# dmpac_targetdb register map
Vendor: Texas Instruments
Registers are 32-bit, read-write, no defined reset value unless marked. A register's access mark holds for its fields unless they carry their own. Offsets are as the file gives them; [hi:lo] are bit positions; {n}, {i} and the like mark numbered series; 'fields as' and 'values as' point back to an identical list.

## DMPAC (part 3 of 5) — Depth and Motion Perception Accelerator (DMPAC)
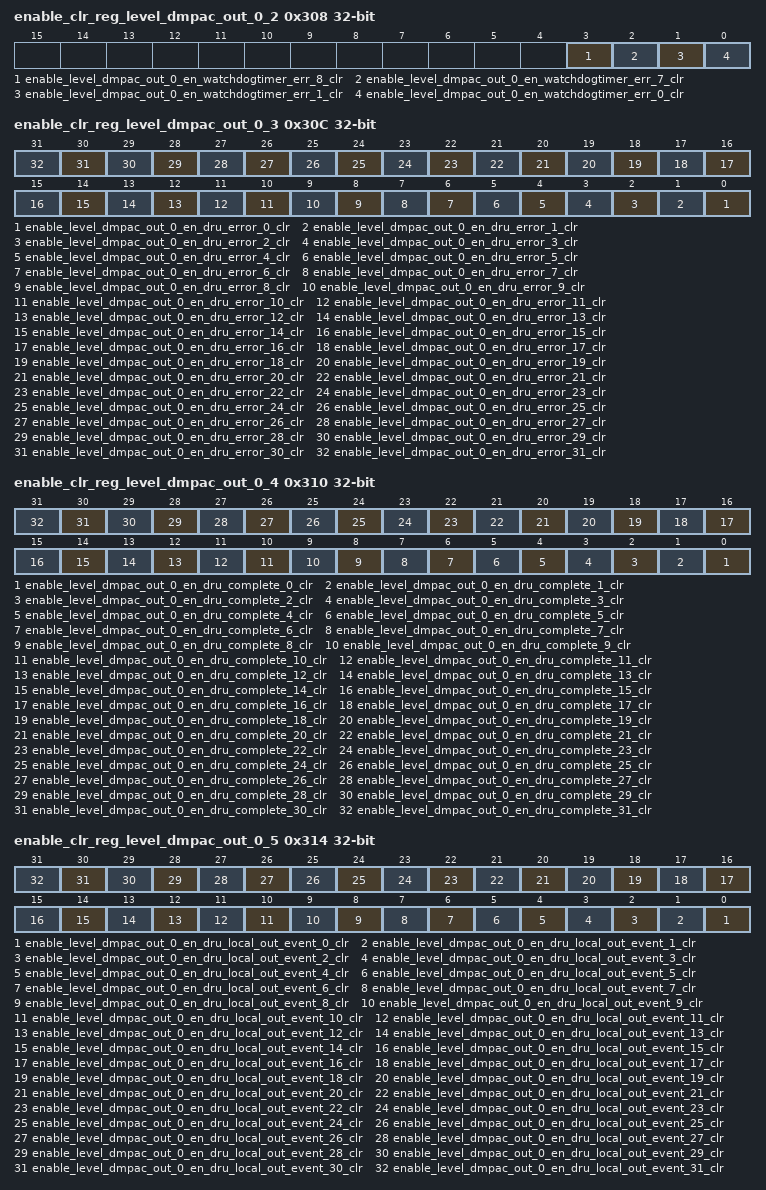
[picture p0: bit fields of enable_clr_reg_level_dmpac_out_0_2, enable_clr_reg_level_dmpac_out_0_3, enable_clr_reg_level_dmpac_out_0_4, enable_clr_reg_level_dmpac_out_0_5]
0x308 enable_clr_reg_level_dmpac_out_0_2 — Enable Clear Register 2
  [3] enable_level_dmpac_out_0_en_watchdogtimer_err_8_clr — Enable Clear for level_dmpac_out_0_en_watchdogtimer_err_8
  [2] enable_level_dmpac_out_0_en_watchdogtimer_err_7_clr — Enable Clear for level_dmpac_out_0_en_watchdogtimer_err_7
  [1] enable_level_dmpac_out_0_en_watchdogtimer_err_1_clr — Enable Clear for level_dmpac_out_0_en_watchdogtimer_err_1
  [0] enable_level_dmpac_out_0_en_watchdogtimer_err_0_clr — Enable Clear for level_dmpac_out_0_en_watchdogtimer_err_0
0x30C enable_clr_reg_level_dmpac_out_0_3 — Enable Clear Register 3
  [n] enable_level_dmpac_out_0_en_dru_error_{n}_clr (n=0..31) — Enable Clear for level_dmpac_out_0_en_dru_error_{n}
0x310 enable_clr_reg_level_dmpac_out_0_4 — Enable Clear Register 4
  [n] enable_level_dmpac_out_0_en_dru_complete_{n}_clr (n=0..31) — Enable Clear for level_dmpac_out_0_en_dru_complete_{n}
0x314 enable_clr_reg_level_dmpac_out_0_5 — Enable Clear Register 5
  [n] enable_level_dmpac_out_0_en_dru_local_out_event_{n}_clr (n=0..31) — Enable Clear for level_dmpac_out_0_en_dru_local_out_event_{n}
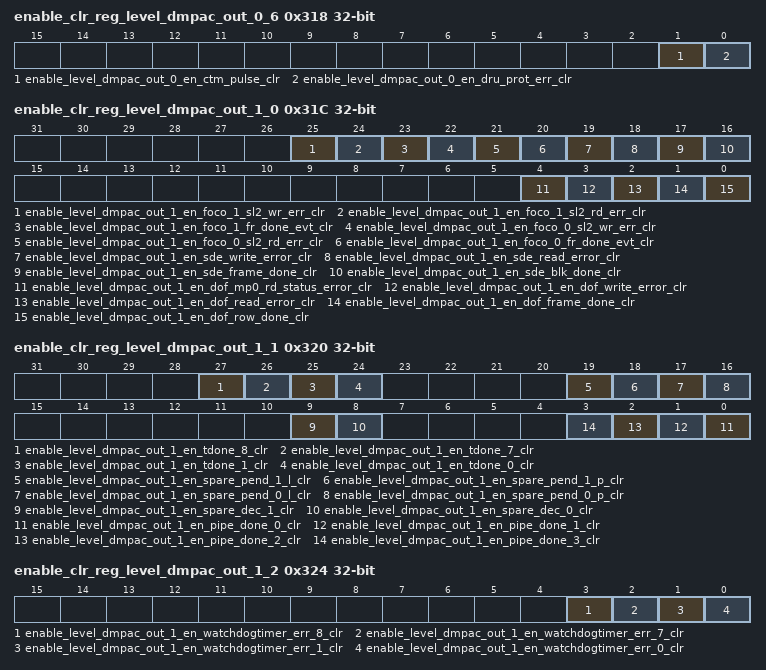
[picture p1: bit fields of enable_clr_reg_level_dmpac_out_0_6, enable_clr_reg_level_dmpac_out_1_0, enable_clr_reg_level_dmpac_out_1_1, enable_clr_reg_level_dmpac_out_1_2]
0x318 enable_clr_reg_level_dmpac_out_0_6 — Enable Clear Register 6
  [1] enable_level_dmpac_out_0_en_ctm_pulse_clr — Enable Clear for level_dmpac_out_0_en_ctm_pulse
  [0] enable_level_dmpac_out_0_en_dru_prot_err_clr — Enable Clear for level_dmpac_out_0_en_dru_prot_err
0x31C enable_clr_reg_level_dmpac_out_1_0 — Enable Clear Register 7
  [25] enable_level_dmpac_out_1_en_foco_1_sl2_wr_err_clr — Enable Clear for level_dmpac_out_1_en_foco_1_sl2_wr_err
  [24] enable_level_dmpac_out_1_en_foco_1_sl2_rd_err_clr — Enable Clear for level_dmpac_out_1_en_foco_1_sl2_rd_err
  [23] enable_level_dmpac_out_1_en_foco_1_fr_done_evt_clr — Enable Clear for level_dmpac_out_1_en_foco_1_fr_done_evt
  [22] enable_level_dmpac_out_1_en_foco_0_sl2_wr_err_clr — Enable Clear for level_dmpac_out_1_en_foco_0_sl2_wr_err
  [21] enable_level_dmpac_out_1_en_foco_0_sl2_rd_err_clr — Enable Clear for level_dmpac_out_1_en_foco_0_sl2_rd_err
  [20] enable_level_dmpac_out_1_en_foco_0_fr_done_evt_clr — Enable Clear for level_dmpac_out_1_en_foco_0_fr_done_evt
  [19] enable_level_dmpac_out_1_en_sde_write_error_clr — Enable Clear for level_dmpac_out_1_en_sde_write_error
  [18] enable_level_dmpac_out_1_en_sde_read_error_clr — Enable Clear for level_dmpac_out_1_en_sde_read_error
  [17] enable_level_dmpac_out_1_en_sde_frame_done_clr — Enable Clear for level_dmpac_out_1_en_sde_frame_done
  [16] enable_level_dmpac_out_1_en_sde_blk_done_clr — Enable Clear for level_dmpac_out_1_en_sde_blk_done
  [4] enable_level_dmpac_out_1_en_dof_mp0_rd_status_error_clr — Enable Clear for level_dmpac_out_1_en_dof_mp0_rd_status_error
  [3] enable_level_dmpac_out_1_en_dof_write_error_clr — Enable Clear for level_dmpac_out_1_en_dof_write_error
  [2] enable_level_dmpac_out_1_en_dof_read_error_clr — Enable Clear for level_dmpac_out_1_en_dof_read_error
  [1] enable_level_dmpac_out_1_en_dof_frame_done_clr — Enable Clear for level_dmpac_out_1_en_dof_frame_done
  [0] enable_level_dmpac_out_1_en_dof_row_done_clr — Enable Clear for level_dmpac_out_1_en_dof_row_done
0x320 enable_clr_reg_level_dmpac_out_1_1 — Enable Clear Register 8
  [27] enable_level_dmpac_out_1_en_tdone_8_clr — Enable Clear for level_dmpac_out_1_en_tdone_8
  [26] enable_level_dmpac_out_1_en_tdone_7_clr — Enable Clear for level_dmpac_out_1_en_tdone_7
  [25] enable_level_dmpac_out_1_en_tdone_1_clr — Enable Clear for level_dmpac_out_1_en_tdone_1
  [24] enable_level_dmpac_out_1_en_tdone_0_clr — Enable Clear for level_dmpac_out_1_en_tdone_0
  [19] enable_level_dmpac_out_1_en_spare_pend_1_l_clr — Enable Clear for level_dmpac_out_1_en_spare_pend_1_l
  [18] enable_level_dmpac_out_1_en_spare_pend_1_p_clr — Enable Clear for level_dmpac_out_1_en_spare_pend_1_p
  [17] enable_level_dmpac_out_1_en_spare_pend_0_l_clr — Enable Clear for level_dmpac_out_1_en_spare_pend_0_l
  [16] enable_level_dmpac_out_1_en_spare_pend_0_p_clr — Enable Clear for level_dmpac_out_1_en_spare_pend_0_p
  [9] enable_level_dmpac_out_1_en_spare_dec_1_clr — Enable Clear for level_dmpac_out_1_en_spare_dec_1
  [8] enable_level_dmpac_out_1_en_spare_dec_0_clr — Enable Clear for level_dmpac_out_1_en_spare_dec_0
  [n] enable_level_dmpac_out_1_en_pipe_done_{n}_clr (n=0..3) — Enable Clear for level_dmpac_out_1_en_pipe_done_{n}
0x324 enable_clr_reg_level_dmpac_out_1_2 — Enable Clear Register 9
  [3] enable_level_dmpac_out_1_en_watchdogtimer_err_8_clr — Enable Clear for level_dmpac_out_1_en_watchdogtimer_err_8
  [2] enable_level_dmpac_out_1_en_watchdogtimer_err_7_clr — Enable Clear for level_dmpac_out_1_en_watchdogtimer_err_7
  [1] enable_level_dmpac_out_1_en_watchdogtimer_err_1_clr — Enable Clear for level_dmpac_out_1_en_watchdogtimer_err_1
  [0] enable_level_dmpac_out_1_en_watchdogtimer_err_0_clr — Enable Clear for level_dmpac_out_1_en_watchdogtimer_err_0
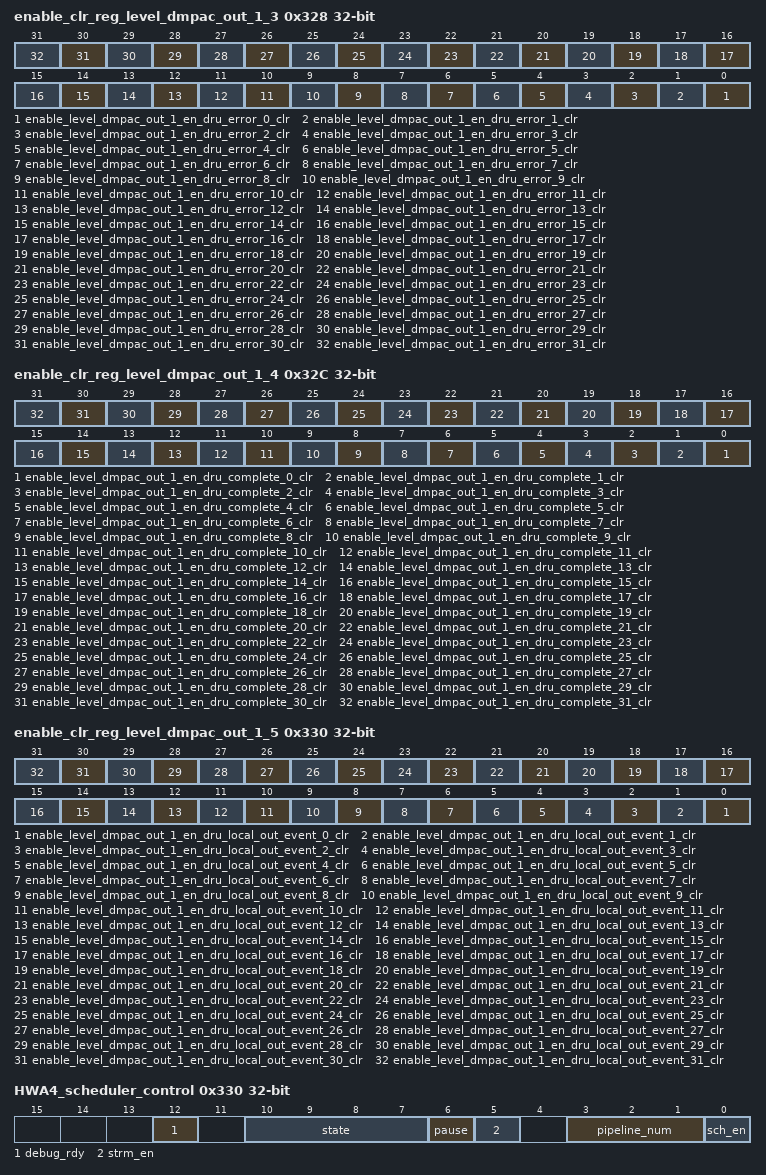
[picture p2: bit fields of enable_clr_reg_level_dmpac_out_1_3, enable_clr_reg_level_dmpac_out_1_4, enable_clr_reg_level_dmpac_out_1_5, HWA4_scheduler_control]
0x328 enable_clr_reg_level_dmpac_out_1_3 — Enable Clear Register 10
  [n] enable_level_dmpac_out_1_en_dru_error_{n}_clr (n=0..31) — Enable Clear for level_dmpac_out_1_en_dru_error_{n}
0x32C enable_clr_reg_level_dmpac_out_1_4 — Enable Clear Register 11
  [n] enable_level_dmpac_out_1_en_dru_complete_{n}_clr (n=0..31) — Enable Clear for level_dmpac_out_1_en_dru_complete_{n}
0x330 enable_clr_reg_level_dmpac_out_1_5 — Enable Clear Register 12
  [n] enable_level_dmpac_out_1_en_dru_local_out_event_{n}_clr (n=0..31) — Enable Clear for level_dmpac_out_1_en_dru_local_out_event_{n}
0x330 HWA4_scheduler_control access per field — Scheduler Control Register
  [12] debug_rdy rw — '0' -> HWA4 Scheduler resources must not be read during halted state. '1'-> HWA4 Scheduler resources are readable during halted state
  [10:7] state ro — Current state of HWA4 Scheduler
  [6] pause rw — '1' -> pause/suspend scheduler , '0' -> resume scheduler
  [5] strm_en rw — '1' -> Streaming input enable, '0' No streaming input
  [3:1] pipeline_num rw — Pipeline Number of HWA4 Scheduler
  [0] sch_en rw — scheduler enable; write '1' to enable scheduler
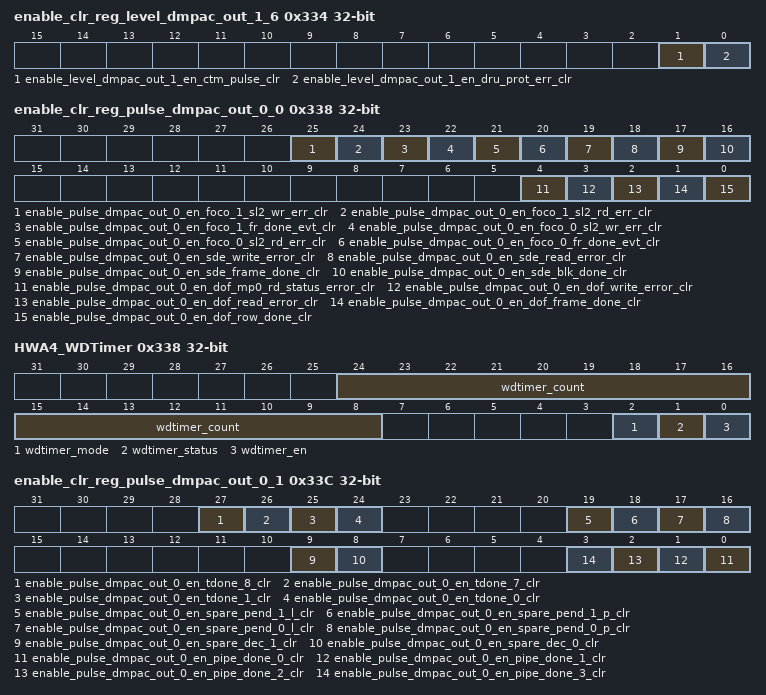
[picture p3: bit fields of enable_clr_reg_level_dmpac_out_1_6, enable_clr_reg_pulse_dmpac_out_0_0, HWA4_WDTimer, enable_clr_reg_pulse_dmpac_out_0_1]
0x334 enable_clr_reg_level_dmpac_out_1_6 — Enable Clear Register 13
  [1] enable_level_dmpac_out_1_en_ctm_pulse_clr — Enable Clear for level_dmpac_out_1_en_ctm_pulse
  [0] enable_level_dmpac_out_1_en_dru_prot_err_clr — Enable Clear for level_dmpac_out_1_en_dru_prot_err
0x338 enable_clr_reg_pulse_dmpac_out_0_0 — Enable Clear Register 14
  [25] enable_pulse_dmpac_out_0_en_foco_1_sl2_wr_err_clr — Enable Clear for pulse_dmpac_out_0_en_foco_1_sl2_wr_err
  [24] enable_pulse_dmpac_out_0_en_foco_1_sl2_rd_err_clr — Enable Clear for pulse_dmpac_out_0_en_foco_1_sl2_rd_err
  [23] enable_pulse_dmpac_out_0_en_foco_1_fr_done_evt_clr — Enable Clear for pulse_dmpac_out_0_en_foco_1_fr_done_evt
  [22] enable_pulse_dmpac_out_0_en_foco_0_sl2_wr_err_clr — Enable Clear for pulse_dmpac_out_0_en_foco_0_sl2_wr_err
  [21] enable_pulse_dmpac_out_0_en_foco_0_sl2_rd_err_clr — Enable Clear for pulse_dmpac_out_0_en_foco_0_sl2_rd_err
  [20] enable_pulse_dmpac_out_0_en_foco_0_fr_done_evt_clr — Enable Clear for pulse_dmpac_out_0_en_foco_0_fr_done_evt
  [19] enable_pulse_dmpac_out_0_en_sde_write_error_clr — Enable Clear for pulse_dmpac_out_0_en_sde_write_error
  [18] enable_pulse_dmpac_out_0_en_sde_read_error_clr — Enable Clear for pulse_dmpac_out_0_en_sde_read_error
  [17] enable_pulse_dmpac_out_0_en_sde_frame_done_clr — Enable Clear for pulse_dmpac_out_0_en_sde_frame_done
  [16] enable_pulse_dmpac_out_0_en_sde_blk_done_clr — Enable Clear for pulse_dmpac_out_0_en_sde_blk_done
  [4] enable_pulse_dmpac_out_0_en_dof_mp0_rd_status_error_clr — Enable Clear for pulse_dmpac_out_0_en_dof_mp0_rd_status_error
  [3] enable_pulse_dmpac_out_0_en_dof_write_error_clr — Enable Clear for pulse_dmpac_out_0_en_dof_write_error
  [2] enable_pulse_dmpac_out_0_en_dof_read_error_clr — Enable Clear for pulse_dmpac_out_0_en_dof_read_error
  [1] enable_pulse_dmpac_out_0_en_dof_frame_done_clr — Enable Clear for pulse_dmpac_out_0_en_dof_frame_done
  [0] enable_pulse_dmpac_out_0_en_dof_row_done_clr — Enable Clear for pulse_dmpac_out_0_en_dof_row_done
0x338 HWA4_WDTimer access per field — Watchdog timer control register
  [24:8] wdtimer_count ro — Current value of HWA4 Scheduler watchdog timer count
  [2] wdtimer_mode rw — Watchdog timeout count '1' -> 128K , '0' -> 64K
  [1] wdtimer_status ro — HWA4 Scheduler watchdog timer status '1' -> Timer Active '0' -> Timer Inactive (count is stable)
  [0] wdtimer_en rw — '1' -> activate watchdog timer for 64K VPAC/DMPAC cycles between task start and task done '0' -> Disable watchdog timer
0x33C enable_clr_reg_pulse_dmpac_out_0_1 — Enable Clear Register 15
  [27] enable_pulse_dmpac_out_0_en_tdone_8_clr — Enable Clear for pulse_dmpac_out_0_en_tdone_8
  [26] enable_pulse_dmpac_out_0_en_tdone_7_clr — Enable Clear for pulse_dmpac_out_0_en_tdone_7
  [25] enable_pulse_dmpac_out_0_en_tdone_1_clr — Enable Clear for pulse_dmpac_out_0_en_tdone_1
  [24] enable_pulse_dmpac_out_0_en_tdone_0_clr — Enable Clear for pulse_dmpac_out_0_en_tdone_0
  [19] enable_pulse_dmpac_out_0_en_spare_pend_1_l_clr — Enable Clear for pulse_dmpac_out_0_en_spare_pend_1_l
  [18] enable_pulse_dmpac_out_0_en_spare_pend_1_p_clr — Enable Clear for pulse_dmpac_out_0_en_spare_pend_1_p
  [17] enable_pulse_dmpac_out_0_en_spare_pend_0_l_clr — Enable Clear for pulse_dmpac_out_0_en_spare_pend_0_l
  [16] enable_pulse_dmpac_out_0_en_spare_pend_0_p_clr — Enable Clear for pulse_dmpac_out_0_en_spare_pend_0_p
  [9] enable_pulse_dmpac_out_0_en_spare_dec_1_clr — Enable Clear for pulse_dmpac_out_0_en_spare_dec_1
  [8] enable_pulse_dmpac_out_0_en_spare_dec_0_clr — Enable Clear for pulse_dmpac_out_0_en_spare_dec_0
  [n] enable_pulse_dmpac_out_0_en_pipe_done_{n}_clr (n=0..3) — Enable Clear for pulse_dmpac_out_0_en_pipe_done_{n}
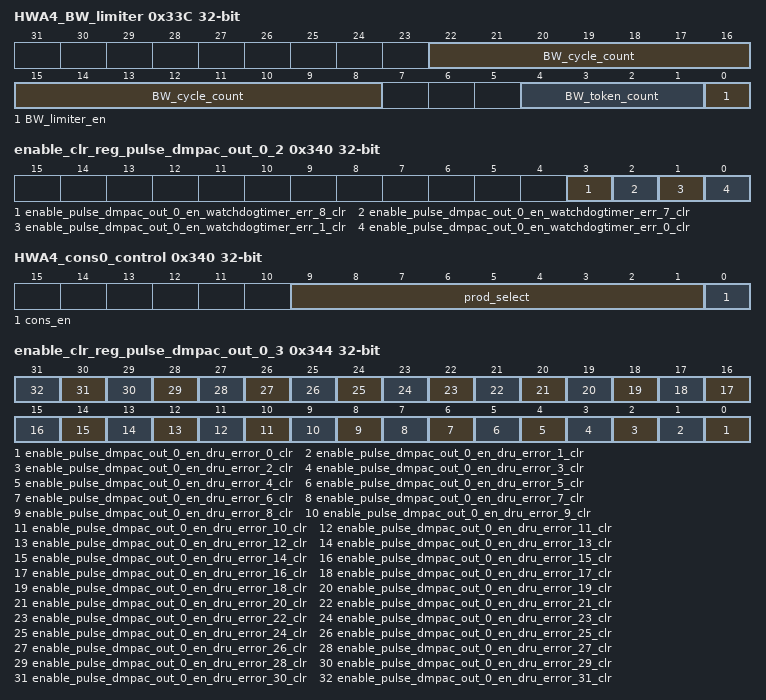
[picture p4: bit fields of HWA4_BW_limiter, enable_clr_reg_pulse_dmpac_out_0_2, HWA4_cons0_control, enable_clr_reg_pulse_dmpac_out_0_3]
0x33C HWA4_BW_limiter — Scheduler BW Control Register. Processing unit level BW control. Use DMA to eliminate peak system BW within processing units line/Block
  [22:8] BW_cycle_count — Average Cycle count between successive Task Start
  [4:1] BW_token_count — Max Token count to create average BW
  [0] BW_limiter_en — '1' -> Enable BW limiter function for HWA4 sch, '0' --> Disable
0x340 enable_clr_reg_pulse_dmpac_out_0_2 — Enable Clear Register 16
  [3] enable_pulse_dmpac_out_0_en_watchdogtimer_err_8_clr — Enable Clear for pulse_dmpac_out_0_en_watchdogtimer_err_8
  [2] enable_pulse_dmpac_out_0_en_watchdogtimer_err_7_clr — Enable Clear for pulse_dmpac_out_0_en_watchdogtimer_err_7
  [1] enable_pulse_dmpac_out_0_en_watchdogtimer_err_1_clr — Enable Clear for pulse_dmpac_out_0_en_watchdogtimer_err_1
  [0] enable_pulse_dmpac_out_0_en_watchdogtimer_err_0_clr — Enable Clear for pulse_dmpac_out_0_en_watchdogtimer_err_0
0x340 HWA4_cons0_control — Controlling consumer socket 0 for HWA4
  [9:1] prod_select — producer select for HWA4 cons socket 0
  [0] cons_en — '1' -> Consumer socket 0 enable , '0' Disable
0x344 enable_clr_reg_pulse_dmpac_out_0_3 — Enable Clear Register 17
  [n] enable_pulse_dmpac_out_0_en_dru_error_{n}_clr (n=0..31) — Enable Clear for pulse_dmpac_out_0_en_dru_error_{n}
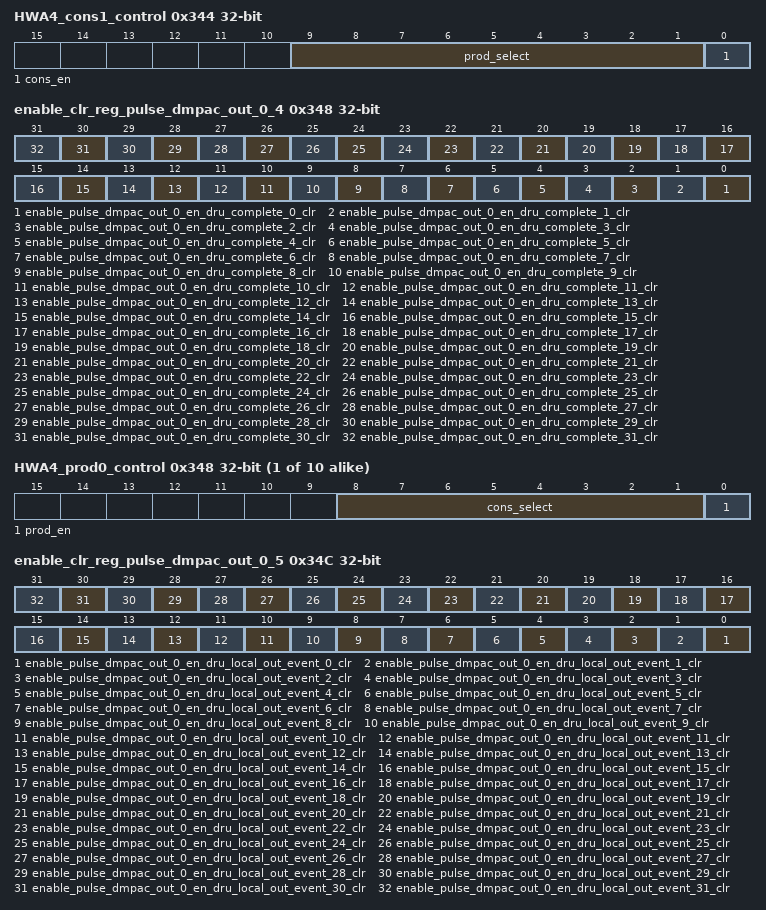
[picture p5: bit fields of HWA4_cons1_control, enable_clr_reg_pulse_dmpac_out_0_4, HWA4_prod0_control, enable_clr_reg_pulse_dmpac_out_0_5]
0x344 HWA4_cons1_control — Controlling consumer socket 1 for HWA4
  [9:1] prod_select — producer select for HWA4 cons socket 1
  [0] cons_en — '1' -> Consumer socket 1 enable , '0' Disable
0x348 enable_clr_reg_pulse_dmpac_out_0_4 — Enable Clear Register 18
  [n] enable_pulse_dmpac_out_0_en_dru_complete_{n}_clr (n=0..31) — Enable Clear for pulse_dmpac_out_0_en_dru_complete_{n}
{0x348+0x14*i} HWA4_prod{i}_control (i=0..9) — Controlling producer socket{i} for HWA4
  [8:1] cons_select — consumer select for HWA4 prod socket {i}. Used in decrementing count of producer buffer
  [0] prod_en — '1' -> Producer socket 0 enable , '0' Disable
0x34C enable_clr_reg_pulse_dmpac_out_0_5 — Enable Clear Register 19
  [n] enable_pulse_dmpac_out_0_en_dru_local_out_event_{n}_clr (n=0..31) — Enable Clear for pulse_dmpac_out_0_en_dru_local_out_event_{n}
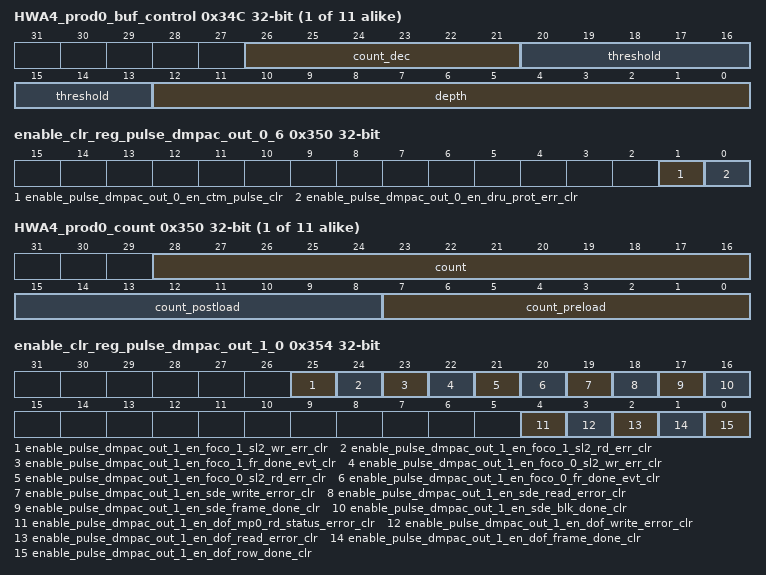
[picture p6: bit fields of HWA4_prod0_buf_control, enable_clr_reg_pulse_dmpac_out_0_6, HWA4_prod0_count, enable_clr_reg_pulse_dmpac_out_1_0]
{0x34C+0x14*i} HWA4_prod{i}_buf_control (i=0..10) — Controlling producer socket{i} buffer for HWA4
  [26:21] count_dec — Count decrement value for prod count
  [20:13] threshold — Count threshold to generate pend for consumer
  [12:0] depth — Maximum number of producer buffer count
0x350 enable_clr_reg_pulse_dmpac_out_0_6 — Enable Clear Register 20
  [1] enable_pulse_dmpac_out_0_en_ctm_pulse_clr — Enable Clear for pulse_dmpac_out_0_en_ctm_pulse
  [0] enable_pulse_dmpac_out_0_en_dru_prot_err_clr — Enable Clear for pulse_dmpac_out_0_en_dru_prot_err
{0x350+0x14*i} HWA4_prod{i}_count access per field (i=0..10) — Defining count values for pre/post load for generating pend by HWA4 prod{i}
  [28:16] count ro — current count value
  [15:8] count_postload rw — count postload after producer max thread count reached
  [7:0] count_preload rw — count preload after scheduler start/init
0x354 enable_clr_reg_pulse_dmpac_out_1_0 — Enable Clear Register 21
  [25] enable_pulse_dmpac_out_1_en_foco_1_sl2_wr_err_clr — Enable Clear for pulse_dmpac_out_1_en_foco_1_sl2_wr_err
  [24] enable_pulse_dmpac_out_1_en_foco_1_sl2_rd_err_clr — Enable Clear for pulse_dmpac_out_1_en_foco_1_sl2_rd_err
  [23] enable_pulse_dmpac_out_1_en_foco_1_fr_done_evt_clr — Enable Clear for pulse_dmpac_out_1_en_foco_1_fr_done_evt
  [22] enable_pulse_dmpac_out_1_en_foco_0_sl2_wr_err_clr — Enable Clear for pulse_dmpac_out_1_en_foco_0_sl2_wr_err
  [21] enable_pulse_dmpac_out_1_en_foco_0_sl2_rd_err_clr — Enable Clear for pulse_dmpac_out_1_en_foco_0_sl2_rd_err
  [20] enable_pulse_dmpac_out_1_en_foco_0_fr_done_evt_clr — Enable Clear for pulse_dmpac_out_1_en_foco_0_fr_done_evt
  [19] enable_pulse_dmpac_out_1_en_sde_write_error_clr — Enable Clear for pulse_dmpac_out_1_en_sde_write_error
  [18] enable_pulse_dmpac_out_1_en_sde_read_error_clr — Enable Clear for pulse_dmpac_out_1_en_sde_read_error
  [17] enable_pulse_dmpac_out_1_en_sde_frame_done_clr — Enable Clear for pulse_dmpac_out_1_en_sde_frame_done
  [16] enable_pulse_dmpac_out_1_en_sde_blk_done_clr — Enable Clear for pulse_dmpac_out_1_en_sde_blk_done
  [4] enable_pulse_dmpac_out_1_en_dof_mp0_rd_status_error_clr — Enable Clear for pulse_dmpac_out_1_en_dof_mp0_rd_status_error
  [3] enable_pulse_dmpac_out_1_en_dof_write_error_clr — Enable Clear for pulse_dmpac_out_1_en_dof_write_error
  [2] enable_pulse_dmpac_out_1_en_dof_read_error_clr — Enable Clear for pulse_dmpac_out_1_en_dof_read_error
  [1] enable_pulse_dmpac_out_1_en_dof_frame_done_clr — Enable Clear for pulse_dmpac_out_1_en_dof_frame_done
  [0] enable_pulse_dmpac_out_1_en_dof_row_done_clr — Enable Clear for pulse_dmpac_out_1_en_dof_row_done
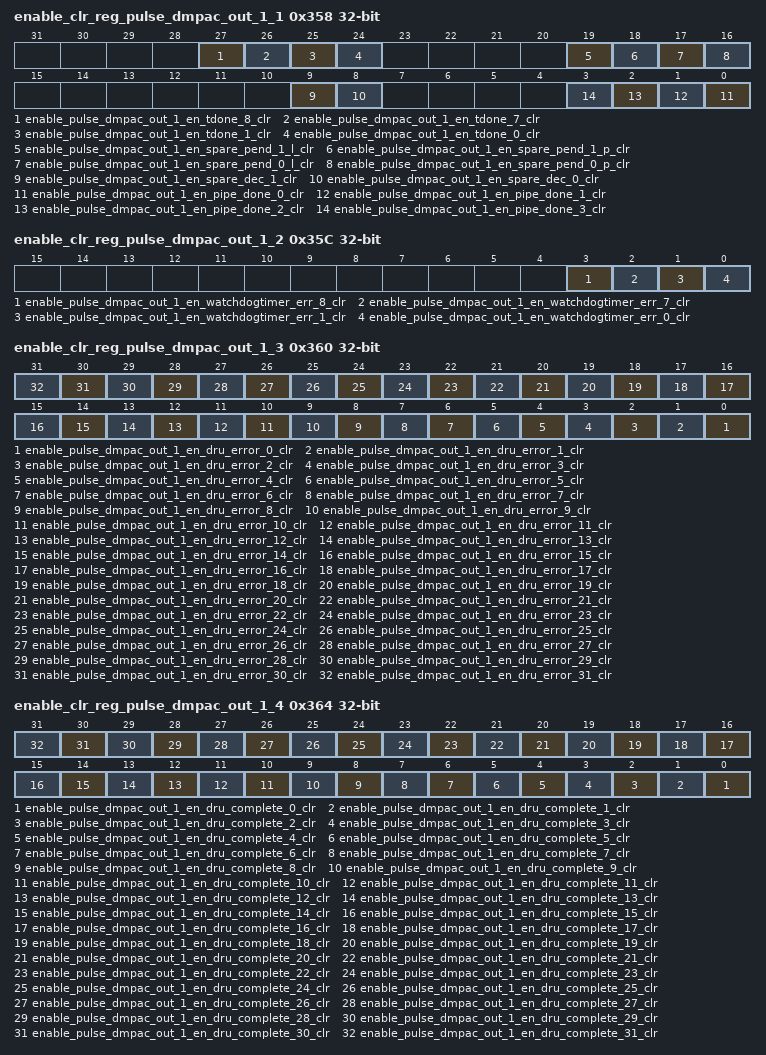
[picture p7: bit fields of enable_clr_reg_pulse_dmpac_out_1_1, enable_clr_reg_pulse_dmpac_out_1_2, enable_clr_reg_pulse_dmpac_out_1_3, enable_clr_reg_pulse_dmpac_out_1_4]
0x358 enable_clr_reg_pulse_dmpac_out_1_1 — Enable Clear Register 22
  [27] enable_pulse_dmpac_out_1_en_tdone_8_clr — Enable Clear for pulse_dmpac_out_1_en_tdone_8
  [26] enable_pulse_dmpac_out_1_en_tdone_7_clr — Enable Clear for pulse_dmpac_out_1_en_tdone_7
  [25] enable_pulse_dmpac_out_1_en_tdone_1_clr — Enable Clear for pulse_dmpac_out_1_en_tdone_1
  [24] enable_pulse_dmpac_out_1_en_tdone_0_clr — Enable Clear for pulse_dmpac_out_1_en_tdone_0
  [19] enable_pulse_dmpac_out_1_en_spare_pend_1_l_clr — Enable Clear for pulse_dmpac_out_1_en_spare_pend_1_l
  [18] enable_pulse_dmpac_out_1_en_spare_pend_1_p_clr — Enable Clear for pulse_dmpac_out_1_en_spare_pend_1_p
  [17] enable_pulse_dmpac_out_1_en_spare_pend_0_l_clr — Enable Clear for pulse_dmpac_out_1_en_spare_pend_0_l
  [16] enable_pulse_dmpac_out_1_en_spare_pend_0_p_clr — Enable Clear for pulse_dmpac_out_1_en_spare_pend_0_p
  [9] enable_pulse_dmpac_out_1_en_spare_dec_1_clr — Enable Clear for pulse_dmpac_out_1_en_spare_dec_1
  [8] enable_pulse_dmpac_out_1_en_spare_dec_0_clr — Enable Clear for pulse_dmpac_out_1_en_spare_dec_0
  [n] enable_pulse_dmpac_out_1_en_pipe_done_{n}_clr (n=0..3) — Enable Clear for pulse_dmpac_out_1_en_pipe_done_{n}
0x35C enable_clr_reg_pulse_dmpac_out_1_2 — Enable Clear Register 23
  [3] enable_pulse_dmpac_out_1_en_watchdogtimer_err_8_clr — Enable Clear for pulse_dmpac_out_1_en_watchdogtimer_err_8
  [2] enable_pulse_dmpac_out_1_en_watchdogtimer_err_7_clr — Enable Clear for pulse_dmpac_out_1_en_watchdogtimer_err_7
  [1] enable_pulse_dmpac_out_1_en_watchdogtimer_err_1_clr — Enable Clear for pulse_dmpac_out_1_en_watchdogtimer_err_1
  [0] enable_pulse_dmpac_out_1_en_watchdogtimer_err_0_clr — Enable Clear for pulse_dmpac_out_1_en_watchdogtimer_err_0
0x360 enable_clr_reg_pulse_dmpac_out_1_3 — Enable Clear Register 24
  [n] enable_pulse_dmpac_out_1_en_dru_error_{n}_clr (n=0..31) — Enable Clear for pulse_dmpac_out_1_en_dru_error_{n}
0x364 enable_clr_reg_pulse_dmpac_out_1_4 — Enable Clear Register 25
  [n] enable_pulse_dmpac_out_1_en_dru_complete_{n}_clr (n=0..31) — Enable Clear for pulse_dmpac_out_1_en_dru_complete_{n}
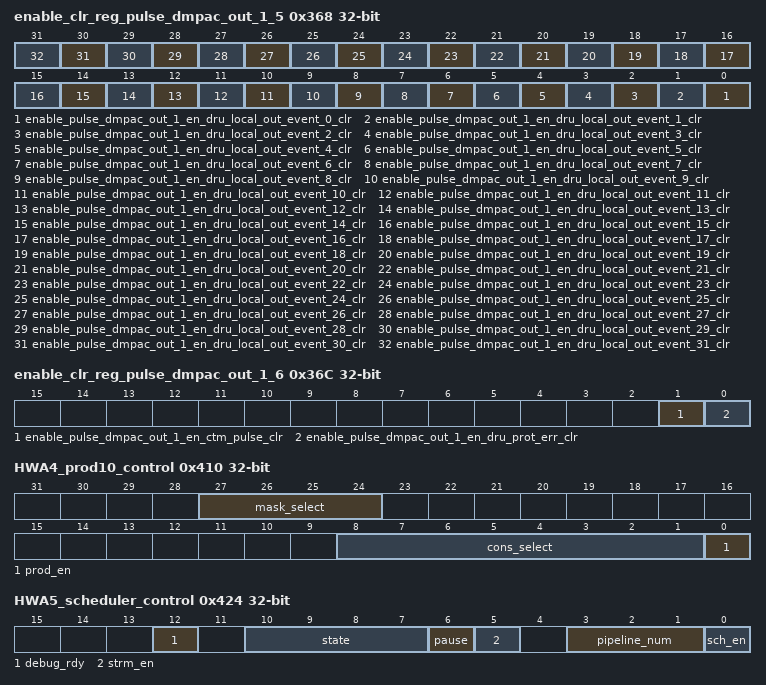
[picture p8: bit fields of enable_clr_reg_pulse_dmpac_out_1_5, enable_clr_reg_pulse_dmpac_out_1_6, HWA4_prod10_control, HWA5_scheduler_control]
0x368 enable_clr_reg_pulse_dmpac_out_1_5 — Enable Clear Register 26
  [n] enable_pulse_dmpac_out_1_en_dru_local_out_event_{n}_clr (n=0..31) — Enable Clear for pulse_dmpac_out_1_en_dru_local_out_event_{n}
0x36C enable_clr_reg_pulse_dmpac_out_1_6 — Enable Clear Register 27
  [1] enable_pulse_dmpac_out_1_en_ctm_pulse_clr — Enable Clear for pulse_dmpac_out_1_en_ctm_pulse
  [0] enable_pulse_dmpac_out_1_en_dru_prot_err_clr — Enable Clear for pulse_dmpac_out_1_en_dru_prot_err
0x400 SRB_S0_RAM ro — srb_s0_ram diagnostic read only port, vbusp will stall until RAM is available for read
  [24:8] rsvd — Always read as 0. Writes have no effect.
  [24:0] data — Data read from RAM
0x400 dmpac_regs_cfg_fw_region_0_control — The FW Region 0 Control Register defines the control fields for the slave dmpac_regs.dmpac_regs_cfg region 0 firewall.
  [4:1] lock — Lock region. Once set region values cannot be modified.
  [8:1] background — Background enable for region. There can be 1 backgroun region per FW and foreground regions can have overlapping addresses only with the background region.
  [9:1] cache_mode — Cache mode for region. Set to 1 to check cache permissions. Set to 0 to ignore cache permissions.
  [4:0] enable — Enable region. A value of 0xA enables, others disable.
{0x404+4i} dmpac_regs_cfg_fw_region_0_permission_{i} (i=0..2) — The FW Region 0 Permission {i} Register defines the permissions for the slave dmpac_regs.dmpac_regs_cfg region 0 firewall.
  [16:8] priv_id — Allowed privid.
  [1] sec_supv_read — Secure supervisor read allowed.
  [2:1] sec_supv_cacheable — Secure supervisor cacheable allowed.
  [3:1] sec_supv_debug — Secure supervisor debug allowed.
  [4:1] sec_user_write — Secure user write allowed.
  [5:1] sec_user_read — Secure user read allowed.
  [6:1] sec_user_cacheable — Secure user cacheable allowed.
  [7:1] sec_user_debug — Secure user debug allowed.
  [8:1] nonsec_supv_write — Non-secure supervisor write allowed.
  [9:1] nonsec_supv_read — Non-secure supervisor read allowed.
  [10:1] nonsec_supv_cacheable — Non-secure supervisor cacheable allowed.
  [11:1] nonsec_supv_debug — Non-secure supervisor debug allowed.
  [12:1] nonsec_user_write — Non-secure user write allowed.
  [13:1] nonsec_user_read — Non-secure user read allowed.
  [14:1] nonsec_user_cacheable — Non-secure user cacheable allowed.
  [15:1] nonsec_user_debug — Non-secure user debug allowed.
  [1:0] sec_supv_write — Secure supervisor write allowed.
0x410 HWA4_prod10_control — Controlling producer socket10 for HWA4
  [27:24] mask_select — define which tdone_mask apply to prod socket 10. tdone_mask[mask_select] applies to prod_socket10
  [8:1] cons_select — consumer select for HWA4 prod socket 10. Used in decrementing count of producer buffer
  [0] prod_en — '1' -> Producer socket 0 enable , '0' Disable
0x410 dmpac_regs_cfg_fw_region_0_start_address_l access per field — The FW Region 0 Start Address Low Register defines the start address bits 31 to 0 for the slave dmpac_regs.dmpac_regs_cfg region 0 firewall.
  [20:12] start_address_l rw — Start address bits 31 to 12. Lowest 12 bits are forced to 0 as address must be 4KB aligned.
  [12:0] start_address_lsb ro — Start address bits 11 to 0 are forced to 0 as address must be 4KB aligned.
0x414 dmpac_regs_cfg_fw_region_0_start_address_h — The FW Region 0 Start Address High Register defines the start address bits 47 to 32 for the slave dmpac_regs.dmpac_regs_cfg region 0 firewall.
  [16:0] start_address_h — Start address bits 47 to 32.
0x418 dmpac_regs_cfg_fw_region_0_end_address_l access per field — The FW Region 0 End Address Low Register defines the end address bits 31 to 0 to include for the slave dmpac_regs.dmpac_regs_cfg region 0 firewall.
  [20:12] end_address_l rw — End address bits 31 to 12 to include in the match. Lowest 12 bits are forced to 1s as address must be 4KB aligned.
  [12:0] end_address_lsb ro — End address bits 11 to 0 are forced to 1s as address must be 4KB aligned minus 1.
0x41C dmpac_regs_cfg_fw_region_0_end_address_h — The FW Region 0 End Address High Register defines the end address bits 47 to 32 to include for the slave dmpac_regs.dmpac_regs_cfg region 0 firewall.
  [16:0] end_address_h — End address bits 47 to 32 to include in the match.
0x424 HWA5_scheduler_control access per field — Scheduler Control Register
  [12] debug_rdy rw — '0' -> HWA5 Scheduler resources must not be read during halted state. '1'-> HWA5 Scheduler resources are readable during halted state
  [10:7] state ro — Current state of HWA5 Scheduler
  [6] pause rw — '1' -> pause/suspend scheduler , '0' -> resume scheduler
  [5] strm_en rw — '1' -> Streaming input enable, '0' No streaming input
  [3:1] pipeline_num rw — Pipeline Number of HWA5 Scheduler
  [0] sch_en rw — scheduler enable; write '1' to enable scheduler
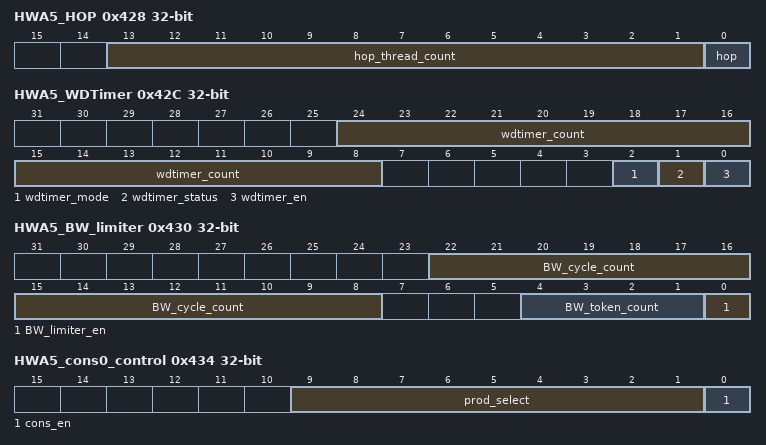
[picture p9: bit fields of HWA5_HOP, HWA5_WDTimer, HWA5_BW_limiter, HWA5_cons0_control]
0x428 HWA5_HOP — Scheduler HOP Control Register. Help in detecting eop within scheduler. Once configured, it counts task/channel starts and stops issuing further starts. Specifically useful for Head of pipe dma scheduler .
  [13:1] hop_thread_count — Number of Task count for Head of pipe
  [0] hop — '1' -> Head of Pipe producer Sch , '0' -> No hop
0x42C HWA5_WDTimer access per field — Watchdog timer control register
  [24:8] wdtimer_count ro — Current value of HWA5 Scheduler watchdog timer count
  [2] wdtimer_mode rw — Watchdog timeout count '1' -> 128K , '0' -> 64K
  [1] wdtimer_status ro — HWA5 Scheduler watchdog timer status '1' -> Timer Active '0' -> Timer Inactive (count is stable)
  [0] wdtimer_en rw — '1' -> activate watchdog timer for 64K VPAC/DMPAC cycles between task start and task done '0' -> Disable watchdog timer
0x430 HWA5_BW_limiter — Scheduler BW Control Register. Processing unit level BW control. Use DMA to eliminate peak system BW within processing units line/Block
  [22:8] BW_cycle_count — Average Cycle count between successive Task Start
  [4:1] BW_token_count — Max Token count to create average BW
  [0] BW_limiter_en — '1' -> Enable BW limiter function for HWA5 sch, '0' --> Disable
0x434 HWA5_cons0_control — Controlling consumer socket 0 for HWA5
  [9:1] prod_select — producer select for HWA5 cons socket 0
  [0] cons_en — '1' -> Consumer socket 0 enable , '0' Disable
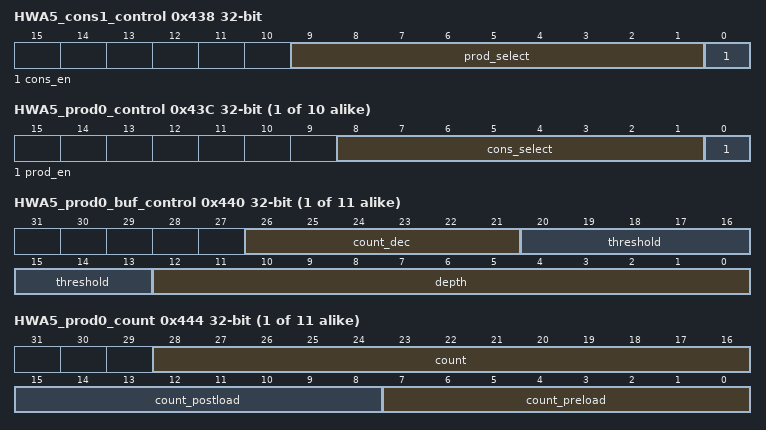
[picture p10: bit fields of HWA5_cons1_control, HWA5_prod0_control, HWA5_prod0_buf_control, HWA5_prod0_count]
0x438 HWA5_cons1_control — Controlling consumer socket 1 for HWA5
  [9:1] prod_select — producer select for HWA5 cons socket 1
  [0] cons_en — '1' -> Consumer socket 1 enable , '0' Disable
{0x43C+0x14*i} HWA5_prod{i}_control (i=0..9) — Controlling producer socket{i} for HWA5
  [8:1] cons_select — consumer select for HWA5 prod socket {i}. Used in decrementing count of producer buffer
  [0] prod_en — '1' -> Producer socket 0 enable , '0' Disable
{0x440+0x14*i} HWA5_prod{i}_buf_control (i=0..10) — Controlling producer socket{i} buffer for HWA5
  fields as HWA4_prod0_buf_control
{0x444+0x14*i} HWA5_prod{i}_count access per field (i=0..10) — Defining count values for pre/post load for generating pend by HWA5 prod{i}
  fields as HWA4_prod0_count
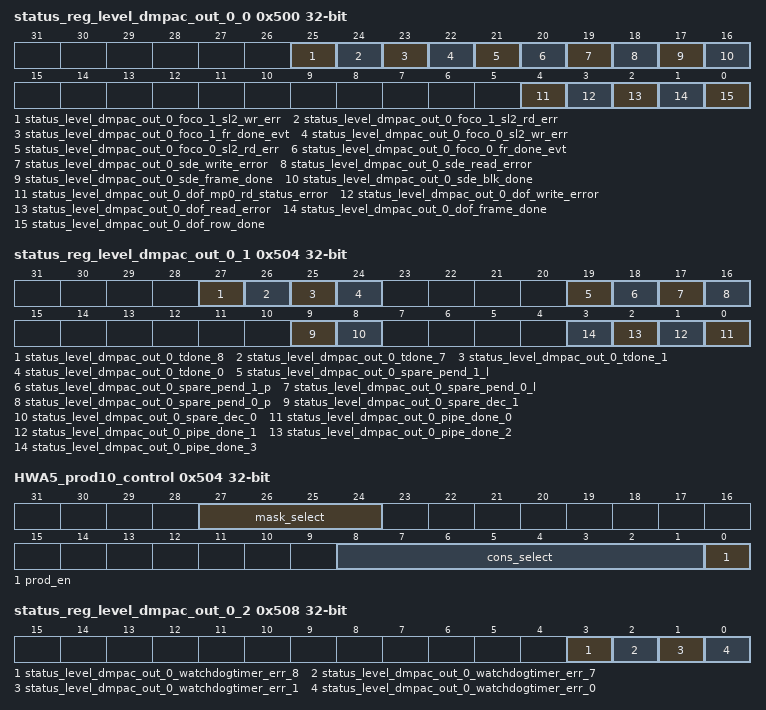
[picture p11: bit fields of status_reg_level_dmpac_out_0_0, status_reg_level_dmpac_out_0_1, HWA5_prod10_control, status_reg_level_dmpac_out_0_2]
0x500 status_reg_level_dmpac_out_0_0 — Status Register 0
  [25] status_level_dmpac_out_0_foco_1_sl2_wr_err — Status ,write 1 to set, for level_dmpac_out_0_en_foco_1_sl2_wr_err
  [24] status_level_dmpac_out_0_foco_1_sl2_rd_err — Status ,write 1 to set, for level_dmpac_out_0_en_foco_1_sl2_rd_err
  [23] status_level_dmpac_out_0_foco_1_fr_done_evt — Status ,write 1 to set, for level_dmpac_out_0_en_foco_1_fr_done_evt
  [22] status_level_dmpac_out_0_foco_0_sl2_wr_err — Status ,write 1 to set, for level_dmpac_out_0_en_foco_0_sl2_wr_err
  [21] status_level_dmpac_out_0_foco_0_sl2_rd_err — Status ,write 1 to set, for level_dmpac_out_0_en_foco_0_sl2_rd_err
  [20] status_level_dmpac_out_0_foco_0_fr_done_evt — Status ,write 1 to set, for level_dmpac_out_0_en_foco_0_fr_done_evt
  [19] status_level_dmpac_out_0_sde_write_error — Status ,write 1 to set, for level_dmpac_out_0_en_sde_write_error
  [18] status_level_dmpac_out_0_sde_read_error — Status ,write 1 to set, for level_dmpac_out_0_en_sde_read_error
  [17] status_level_dmpac_out_0_sde_frame_done — Status ,write 1 to set, for level_dmpac_out_0_en_sde_frame_done
  [16] status_level_dmpac_out_0_sde_blk_done — Status ,write 1 to set, for level_dmpac_out_0_en_sde_blk_done
  [4] status_level_dmpac_out_0_dof_mp0_rd_status_error — Status ,write 1 to set, for level_dmpac_out_0_en_dof_mp0_rd_status_error
  [3] status_level_dmpac_out_0_dof_write_error — Status ,write 1 to set, for level_dmpac_out_0_en_dof_write_error
  [2] status_level_dmpac_out_0_dof_read_error — Status ,write 1 to set, for level_dmpac_out_0_en_dof_read_error
  [1] status_level_dmpac_out_0_dof_frame_done — Status ,write 1 to set, for level_dmpac_out_0_en_dof_frame_done
  [0] status_level_dmpac_out_0_dof_row_done — Status ,write 1 to set, for level_dmpac_out_0_en_dof_row_done
0x504 status_reg_level_dmpac_out_0_1 access per field — Status Register 1
  [27] status_level_dmpac_out_0_tdone_8 rw — Status ,write 1 to set, for level_dmpac_out_0_en_tdone_8
  [26] status_level_dmpac_out_0_tdone_7 rw — Status ,write 1 to set, for level_dmpac_out_0_en_tdone_7
  [25] status_level_dmpac_out_0_tdone_1 rw — Status ,write 1 to set, for level_dmpac_out_0_en_tdone_1
  [24] status_level_dmpac_out_0_tdone_0 rw — Status ,write 1 to set, for level_dmpac_out_0_en_tdone_0
  [19] status_level_dmpac_out_0_spare_pend_1_l ro — Status for level_dmpac_out_0_en_spare_pend_1_l
  [18] status_level_dmpac_out_0_spare_pend_1_p ro — Status for level_dmpac_out_0_en_spare_pend_1_p
  [17] status_level_dmpac_out_0_spare_pend_0_l ro — Status for level_dmpac_out_0_en_spare_pend_0_l
  [16] status_level_dmpac_out_0_spare_pend_0_p ro — Status for level_dmpac_out_0_en_spare_pend_0_p
  [9] status_level_dmpac_out_0_spare_dec_1 rw — Status ,write 1 to set, for level_dmpac_out_0_en_spare_dec_1
  [8] status_level_dmpac_out_0_spare_dec_0 rw — Status ,write 1 to set, for level_dmpac_out_0_en_spare_dec_0
  [n] status_level_dmpac_out_0_pipe_done_{n} rw (n=0..3) — Status ,write 1 to set, for level_dmpac_out_0_en_pipe_done_{n}
0x504 HWA5_prod10_control — Controlling producer socket10 for HWA5
  [27:24] mask_select — define which tdone_mask apply to prod socket 10. tdone_mask[mask_select] applies to prod_socket10
  [8:1] cons_select — consumer select for HWA5 prod socket 10. Used in decrementing count of producer buffer
  [0] prod_en — '1' -> Producer socket 0 enable , '0' Disable
0x508 status_reg_level_dmpac_out_0_2 — Status Register 2
  [3] status_level_dmpac_out_0_watchdogtimer_err_8 — Status ,write 1 to set, for level_dmpac_out_0_en_watchdogtimer_err_8
  [2] status_level_dmpac_out_0_watchdogtimer_err_7 — Status ,write 1 to set, for level_dmpac_out_0_en_watchdogtimer_err_7
  [1] status_level_dmpac_out_0_watchdogtimer_err_1 — Status ,write 1 to set, for level_dmpac_out_0_en_watchdogtimer_err_1
  [0] status_level_dmpac_out_0_watchdogtimer_err_0 — Status ,write 1 to set, for level_dmpac_out_0_en_watchdogtimer_err_0
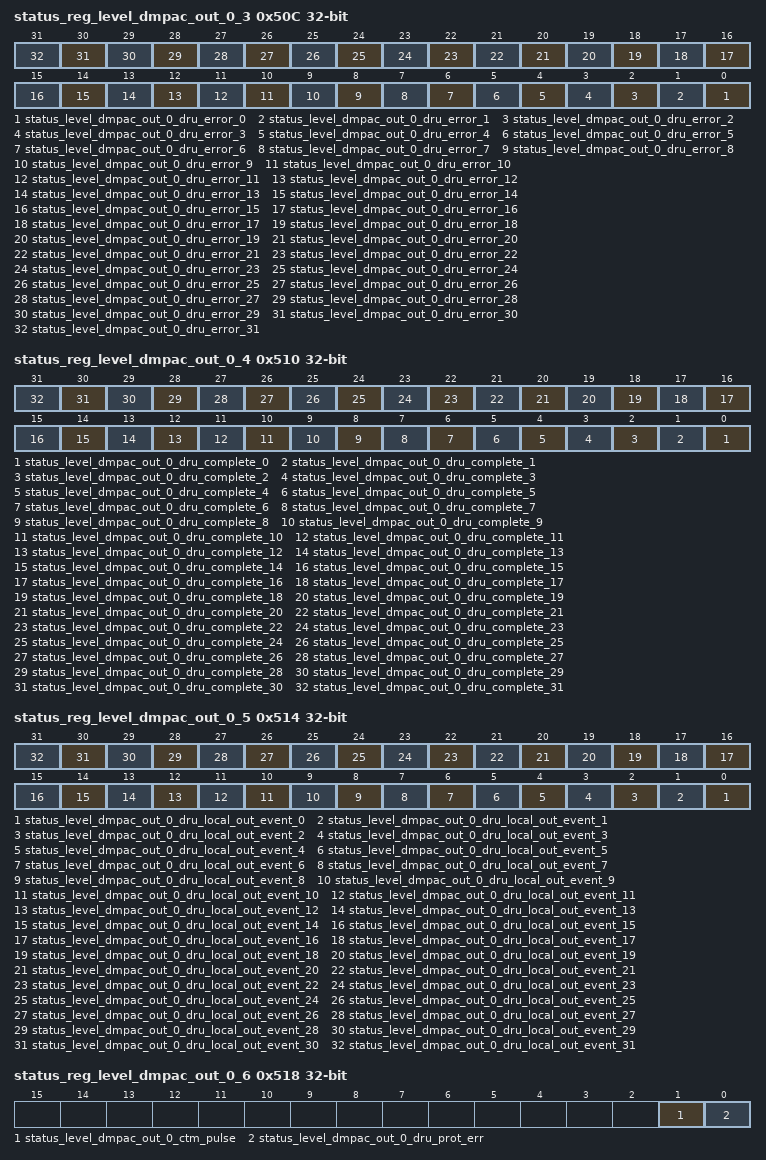
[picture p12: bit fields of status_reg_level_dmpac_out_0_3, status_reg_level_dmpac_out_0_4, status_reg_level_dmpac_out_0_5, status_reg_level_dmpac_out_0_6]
0x50C status_reg_level_dmpac_out_0_3 — Status Register 3
  [n] status_level_dmpac_out_0_dru_error_{n} (n=0..31) — Status ,write 1 to set, for level_dmpac_out_0_en_dru_error_{n}
0x510 status_reg_level_dmpac_out_0_4 — Status Register 4
  [n] status_level_dmpac_out_0_dru_complete_{n} (n=0..31) — Status ,write 1 to set, for level_dmpac_out_0_en_dru_complete_{n}
0x514 status_reg_level_dmpac_out_0_5 — Status Register 5
  [n] status_level_dmpac_out_0_dru_local_out_event_{n} (n=0..31) — Status ,write 1 to set, for level_dmpac_out_0_en_dru_local_out_event_{n}
0x518 status_reg_level_dmpac_out_0_6 — Status Register 6
  [1] status_level_dmpac_out_0_ctm_pulse — Status ,write 1 to set, for level_dmpac_out_0_en_ctm_pulse
  [0] status_level_dmpac_out_0_dru_prot_err — Status ,write 1 to set, for level_dmpac_out_0_en_dru_prot_err
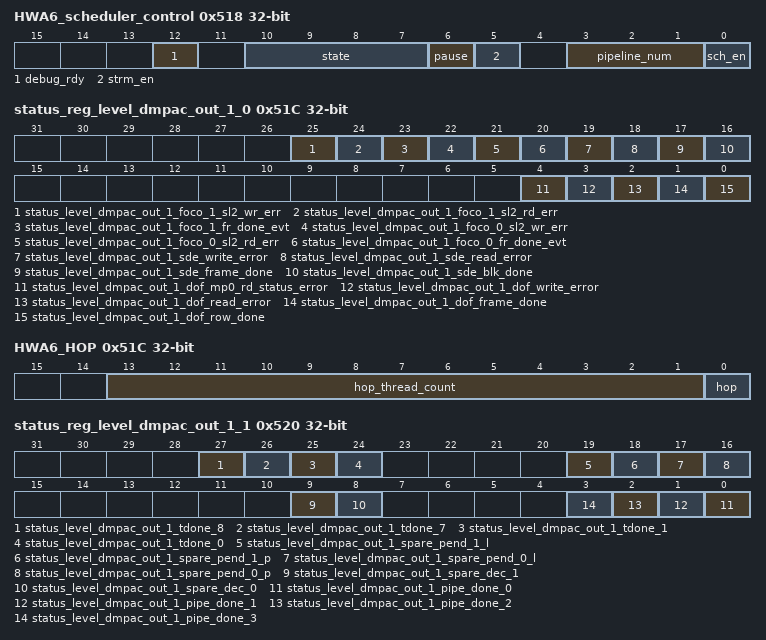
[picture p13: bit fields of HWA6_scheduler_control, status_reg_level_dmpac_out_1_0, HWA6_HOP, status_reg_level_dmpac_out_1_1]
0x518 HWA6_scheduler_control access per field — Scheduler Control Register
  [12] debug_rdy rw — '0' -> HWA6 Scheduler resources must not be read during halted state. '1'-> HWA6 Scheduler resources are readable during halted state
  [10:7] state ro — Current state of HWA6 Scheduler
  [6] pause rw — '1' -> pause/suspend scheduler , '0' -> resume scheduler
  [5] strm_en rw — '1' -> Streaming input enable, '0' No streaming input
  [3:1] pipeline_num rw — Pipeline Number of HWA6 Scheduler
  [0] sch_en rw — scheduler enable; write '1' to enable scheduler
0x51C status_reg_level_dmpac_out_1_0 — Status Register 7
  [25] status_level_dmpac_out_1_foco_1_sl2_wr_err — Status ,write 1 to set, for level_dmpac_out_1_en_foco_1_sl2_wr_err
  [24] status_level_dmpac_out_1_foco_1_sl2_rd_err — Status ,write 1 to set, for level_dmpac_out_1_en_foco_1_sl2_rd_err
  [23] status_level_dmpac_out_1_foco_1_fr_done_evt — Status ,write 1 to set, for level_dmpac_out_1_en_foco_1_fr_done_evt
  [22] status_level_dmpac_out_1_foco_0_sl2_wr_err — Status ,write 1 to set, for level_dmpac_out_1_en_foco_0_sl2_wr_err
  [21] status_level_dmpac_out_1_foco_0_sl2_rd_err — Status ,write 1 to set, for level_dmpac_out_1_en_foco_0_sl2_rd_err
  [20] status_level_dmpac_out_1_foco_0_fr_done_evt — Status ,write 1 to set, for level_dmpac_out_1_en_foco_0_fr_done_evt
  [19] status_level_dmpac_out_1_sde_write_error — Status ,write 1 to set, for level_dmpac_out_1_en_sde_write_error
  [18] status_level_dmpac_out_1_sde_read_error — Status ,write 1 to set, for level_dmpac_out_1_en_sde_read_error
  [17] status_level_dmpac_out_1_sde_frame_done — Status ,write 1 to set, for level_dmpac_out_1_en_sde_frame_done
  [16] status_level_dmpac_out_1_sde_blk_done — Status ,write 1 to set, for level_dmpac_out_1_en_sde_blk_done
  [4] status_level_dmpac_out_1_dof_mp0_rd_status_error — Status ,write 1 to set, for level_dmpac_out_1_en_dof_mp0_rd_status_error
  [3] status_level_dmpac_out_1_dof_write_error — Status ,write 1 to set, for level_dmpac_out_1_en_dof_write_error
  [2] status_level_dmpac_out_1_dof_read_error — Status ,write 1 to set, for level_dmpac_out_1_en_dof_read_error
  [1] status_level_dmpac_out_1_dof_frame_done — Status ,write 1 to set, for level_dmpac_out_1_en_dof_frame_done
  [0] status_level_dmpac_out_1_dof_row_done — Status ,write 1 to set, for level_dmpac_out_1_en_dof_row_done
0x51C HWA6_HOP — Scheduler HOP Control Register. Help in detecting eop within scheduler. Once configured, it counts task/channel starts and stops issuing further starts. Specifically useful for Head of pipe dma scheduler .
  fields as HWA5_HOP
0x520 status_reg_level_dmpac_out_1_1 access per field — Status Register 8
  [27] status_level_dmpac_out_1_tdone_8 rw — Status ,write 1 to set, for level_dmpac_out_1_en_tdone_8
  [26] status_level_dmpac_out_1_tdone_7 rw — Status ,write 1 to set, for level_dmpac_out_1_en_tdone_7
  [25] status_level_dmpac_out_1_tdone_1 rw — Status ,write 1 to set, for level_dmpac_out_1_en_tdone_1
  [24] status_level_dmpac_out_1_tdone_0 rw — Status ,write 1 to set, for level_dmpac_out_1_en_tdone_0
  [19] status_level_dmpac_out_1_spare_pend_1_l ro — Status for level_dmpac_out_1_en_spare_pend_1_l
  [18] status_level_dmpac_out_1_spare_pend_1_p ro — Status for level_dmpac_out_1_en_spare_pend_1_p
  [17] status_level_dmpac_out_1_spare_pend_0_l ro — Status for level_dmpac_out_1_en_spare_pend_0_l
  [16] status_level_dmpac_out_1_spare_pend_0_p ro — Status for level_dmpac_out_1_en_spare_pend_0_p
  [9] status_level_dmpac_out_1_spare_dec_1 rw — Status ,write 1 to set, for level_dmpac_out_1_en_spare_dec_1
  [8] status_level_dmpac_out_1_spare_dec_0 rw — Status ,write 1 to set, for level_dmpac_out_1_en_spare_dec_0
  [n] status_level_dmpac_out_1_pipe_done_{n} rw (n=0..3) — Status ,write 1 to set, for level_dmpac_out_1_en_pipe_done_{n}
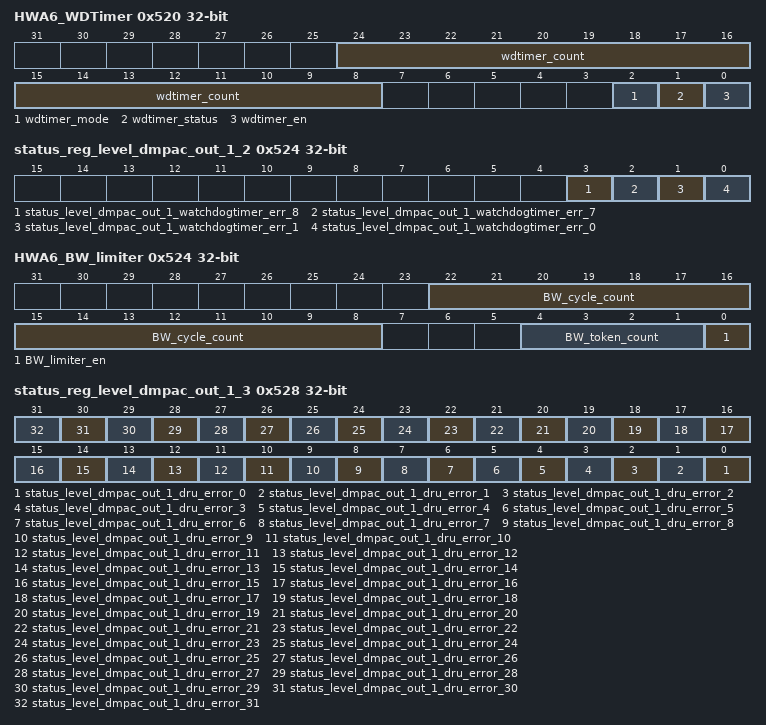
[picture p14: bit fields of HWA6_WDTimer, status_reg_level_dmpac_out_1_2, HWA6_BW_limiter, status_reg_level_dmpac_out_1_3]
0x520 HWA6_WDTimer access per field — Watchdog timer control register
  [24:8] wdtimer_count ro — Current value of HWA6 Scheduler watchdog timer count
  [2] wdtimer_mode rw — Watchdog timeout count '1' -> 128K , '0' -> 64K
  [1] wdtimer_status ro — HWA6 Scheduler watchdog timer status '1' -> Timer Active '0' -> Timer Inactive (count is stable)
  [0] wdtimer_en rw — '1' -> activate watchdog timer for 64K VPAC/DMPAC cycles between task start and task done '0' -> Disable watchdog timer
0x524 status_reg_level_dmpac_out_1_2 — Status Register 9
  [3] status_level_dmpac_out_1_watchdogtimer_err_8 — Status ,write 1 to set, for level_dmpac_out_1_en_watchdogtimer_err_8
  [2] status_level_dmpac_out_1_watchdogtimer_err_7 — Status ,write 1 to set, for level_dmpac_out_1_en_watchdogtimer_err_7
  [1] status_level_dmpac_out_1_watchdogtimer_err_1 — Status ,write 1 to set, for level_dmpac_out_1_en_watchdogtimer_err_1
  [0] status_level_dmpac_out_1_watchdogtimer_err_0 — Status ,write 1 to set, for level_dmpac_out_1_en_watchdogtimer_err_0
0x524 HWA6_BW_limiter — Scheduler BW Control Register. Processing unit level BW control. Use DMA to eliminate peak system BW within processing units line/Block
  [22:8] BW_cycle_count — Average Cycle count between successive Task Start
  [4:1] BW_token_count — Max Token count to create average BW
  [0] BW_limiter_en — '1' -> Enable BW limiter function for HWA6 sch, '0' --> Disable
0x528 status_reg_level_dmpac_out_1_3 — Status Register 10
  [n] status_level_dmpac_out_1_dru_error_{n} (n=0..31) — Status ,write 1 to set, for level_dmpac_out_1_en_dru_error_{n}
0x528 HWA6_cons0_control — Controlling consumer socket 0 for HWA6
  [9:1] prod_select — producer select for HWA6 cons socket 0
  [0] cons_en — '1' -> Consumer socket 0 enable , '0' Disable
0x52C status_reg_level_dmpac_out_1_4 — Status Register 11
  [n] status_level_dmpac_out_1_dru_complete_{n} (n=0..31) — Status ,write 1 to set, for level_dmpac_out_1_en_dru_complete_{n}
0x52C HWA6_cons1_control — Controlling consumer socket 1 for HWA6
  [9:1] prod_select — producer select for HWA6 cons socket 1
  [0] cons_en — '1' -> Consumer socket 1 enable , '0' Disable
0x530 status_reg_level_dmpac_out_1_5 — Status Register 12
  [n] status_level_dmpac_out_1_dru_local_out_event_{n} (n=0..31) — Status ,write 1 to set, for level_dmpac_out_1_en_dru_local_out_event_{n}
0x530 HWA6_prod0_control — Controlling producer socket0 for HWA6
  [8:1] cons_select — consumer select for HWA6 prod socket 0. Used in decrementing count of producer buffer
  [0] prod_en — '1' -> Producer socket 0 enable , '0' Disable
0x534 status_reg_level_dmpac_out_1_6 — Status Register 13
  [1] status_level_dmpac_out_1_ctm_pulse — Status ,write 1 to set, for level_dmpac_out_1_en_ctm_pulse
  [0] status_level_dmpac_out_1_dru_prot_err — Status ,write 1 to set, for level_dmpac_out_1_en_dru_prot_err
0x534 HWA6_prod0_buf_control — Controlling producer socket0 buffer for HWA6
  fields as HWA4_prod0_buf_control
0x538 status_reg_pulse_dmpac_out_0_0 — Status Register 14
  [25] status_pulse_dmpac_out_0_foco_1_sl2_wr_err — Status ,write 1 to set, for pulse_dmpac_out_0_en_foco_1_sl2_wr_err
  [24] status_pulse_dmpac_out_0_foco_1_sl2_rd_err — Status ,write 1 to set, for pulse_dmpac_out_0_en_foco_1_sl2_rd_err
  [23] status_pulse_dmpac_out_0_foco_1_fr_done_evt — Status ,write 1 to set, for pulse_dmpac_out_0_en_foco_1_fr_done_evt
  [22] status_pulse_dmpac_out_0_foco_0_sl2_wr_err — Status ,write 1 to set, for pulse_dmpac_out_0_en_foco_0_sl2_wr_err
  [21] status_pulse_dmpac_out_0_foco_0_sl2_rd_err — Status ,write 1 to set, for pulse_dmpac_out_0_en_foco_0_sl2_rd_err
  [20] status_pulse_dmpac_out_0_foco_0_fr_done_evt — Status ,write 1 to set, for pulse_dmpac_out_0_en_foco_0_fr_done_evt
  [19] status_pulse_dmpac_out_0_sde_write_error — Status ,write 1 to set, for pulse_dmpac_out_0_en_sde_write_error
  [18] status_pulse_dmpac_out_0_sde_read_error — Status ,write 1 to set, for pulse_dmpac_out_0_en_sde_read_error
  [17] status_pulse_dmpac_out_0_sde_frame_done — Status ,write 1 to set, for pulse_dmpac_out_0_en_sde_frame_done
  [16] status_pulse_dmpac_out_0_sde_blk_done — Status ,write 1 to set, for pulse_dmpac_out_0_en_sde_blk_done
  [4] status_pulse_dmpac_out_0_dof_mp0_rd_status_error — Status ,write 1 to set, for pulse_dmpac_out_0_en_dof_mp0_rd_status_error
  [3] status_pulse_dmpac_out_0_dof_write_error — Status ,write 1 to set, for pulse_dmpac_out_0_en_dof_write_error
  [2] status_pulse_dmpac_out_0_dof_read_error — Status ,write 1 to set, for pulse_dmpac_out_0_en_dof_read_error
  [1] status_pulse_dmpac_out_0_dof_frame_done — Status ,write 1 to set, for pulse_dmpac_out_0_en_dof_frame_done
  [0] status_pulse_dmpac_out_0_dof_row_done — Status ,write 1 to set, for pulse_dmpac_out_0_en_dof_row_done
0x538 HWA6_prod0_count access per field — Defining count values for pre/post load for generating pend by HWA6 prod0
  fields as HWA4_prod0_count
0x53C status_reg_pulse_dmpac_out_0_1 access per field — Status Register 15
  [27] status_pulse_dmpac_out_0_tdone_8 rw — Status ,write 1 to set, for pulse_dmpac_out_0_en_tdone_8
  [26] status_pulse_dmpac_out_0_tdone_7 rw — Status ,write 1 to set, for pulse_dmpac_out_0_en_tdone_7
  [25] status_pulse_dmpac_out_0_tdone_1 rw — Status ,write 1 to set, for pulse_dmpac_out_0_en_tdone_1
  [24] status_pulse_dmpac_out_0_tdone_0 rw — Status ,write 1 to set, for pulse_dmpac_out_0_en_tdone_0
  [19] status_pulse_dmpac_out_0_spare_pend_1_l ro — Status for pulse_dmpac_out_0_en_spare_pend_1_l
  [18] status_pulse_dmpac_out_0_spare_pend_1_p ro — Status for pulse_dmpac_out_0_en_spare_pend_1_p
  [17] status_pulse_dmpac_out_0_spare_pend_0_l ro — Status for pulse_dmpac_out_0_en_spare_pend_0_l
  [16] status_pulse_dmpac_out_0_spare_pend_0_p ro — Status for pulse_dmpac_out_0_en_spare_pend_0_p
  [9] status_pulse_dmpac_out_0_spare_dec_1 rw — Status ,write 1 to set, for pulse_dmpac_out_0_en_spare_dec_1
  [8] status_pulse_dmpac_out_0_spare_dec_0 rw — Status ,write 1 to set, for pulse_dmpac_out_0_en_spare_dec_0
  [n] status_pulse_dmpac_out_0_pipe_done_{n} rw (n=0..3) — Status ,write 1 to set, for pulse_dmpac_out_0_en_pipe_done_{n}
0x540 status_reg_pulse_dmpac_out_0_2 — Status Register 16
  [3] status_pulse_dmpac_out_0_watchdogtimer_err_8 — Status ,write 1 to set, for pulse_dmpac_out_0_en_watchdogtimer_err_8
  [2] status_pulse_dmpac_out_0_watchdogtimer_err_7 — Status ,write 1 to set, for pulse_dmpac_out_0_en_watchdogtimer_err_7
  [1] status_pulse_dmpac_out_0_watchdogtimer_err_1 — Status ,write 1 to set, for pulse_dmpac_out_0_en_watchdogtimer_err_1
  [0] status_pulse_dmpac_out_0_watchdogtimer_err_0 — Status ,write 1 to set, for pulse_dmpac_out_0_en_watchdogtimer_err_0
0x544 status_reg_pulse_dmpac_out_0_3 — Status Register 17
  [n] status_pulse_dmpac_out_0_dru_error_{n} (n=0..31) — Status ,write 1 to set, for pulse_dmpac_out_0_en_dru_error_{n}
0x544 HWA6_prod1_control — Controlling producer socket1 for HWA6
  [8:1] cons_select — consumer select for HWA6 prod socket 1. Used in decrementing count of producer buffer
  [0] prod_en — '1' -> Producer socket 0 enable , '0' Disable
0x548 status_reg_pulse_dmpac_out_0_4 — Status Register 18
  [n] status_pulse_dmpac_out_0_dru_complete_{n} (n=0..31) — Status ,write 1 to set, for pulse_dmpac_out_0_en_dru_complete_{n}
0x548 HWA6_prod1_buf_control — Controlling producer socket1 buffer for HWA6
  fields as HWA4_prod0_buf_control
0x54C status_reg_pulse_dmpac_out_0_5 — Status Register 19
  [n] status_pulse_dmpac_out_0_dru_local_out_event_{n} (n=0..31) — Status ,write 1 to set, for pulse_dmpac_out_0_en_dru_local_out_event_{n}
0x54C HWA6_prod1_count access per field — Defining count values for pre/post load for generating pend by HWA6 prod1
  fields as HWA4_prod0_count
0x550 status_reg_pulse_dmpac_out_0_6 — Status Register 20
  [1] status_pulse_dmpac_out_0_ctm_pulse — Status ,write 1 to set, for pulse_dmpac_out_0_en_ctm_pulse
  [0] status_pulse_dmpac_out_0_dru_prot_err — Status ,write 1 to set, for pulse_dmpac_out_0_en_dru_prot_err
0x554 status_reg_pulse_dmpac_out_1_0 — Status Register 21
  [25] status_pulse_dmpac_out_1_foco_1_sl2_wr_err — Status ,write 1 to set, for pulse_dmpac_out_1_en_foco_1_sl2_wr_err
  [24] status_pulse_dmpac_out_1_foco_1_sl2_rd_err — Status ,write 1 to set, for pulse_dmpac_out_1_en_foco_1_sl2_rd_err
  [23] status_pulse_dmpac_out_1_foco_1_fr_done_evt — Status ,write 1 to set, for pulse_dmpac_out_1_en_foco_1_fr_done_evt
  [22] status_pulse_dmpac_out_1_foco_0_sl2_wr_err — Status ,write 1 to set, for pulse_dmpac_out_1_en_foco_0_sl2_wr_err
  [21] status_pulse_dmpac_out_1_foco_0_sl2_rd_err — Status ,write 1 to set, for pulse_dmpac_out_1_en_foco_0_sl2_rd_err
  [20] status_pulse_dmpac_out_1_foco_0_fr_done_evt — Status ,write 1 to set, for pulse_dmpac_out_1_en_foco_0_fr_done_evt
  [19] status_pulse_dmpac_out_1_sde_write_error — Status ,write 1 to set, for pulse_dmpac_out_1_en_sde_write_error
  [18] status_pulse_dmpac_out_1_sde_read_error — Status ,write 1 to set, for pulse_dmpac_out_1_en_sde_read_error
  [17] status_pulse_dmpac_out_1_sde_frame_done — Status ,write 1 to set, for pulse_dmpac_out_1_en_sde_frame_done
  [16] status_pulse_dmpac_out_1_sde_blk_done — Status ,write 1 to set, for pulse_dmpac_out_1_en_sde_blk_done
  [4] status_pulse_dmpac_out_1_dof_mp0_rd_status_error — Status ,write 1 to set, for pulse_dmpac_out_1_en_dof_mp0_rd_status_error
  [3] status_pulse_dmpac_out_1_dof_write_error — Status ,write 1 to set, for pulse_dmpac_out_1_en_dof_write_error
  [2] status_pulse_dmpac_out_1_dof_read_error — Status ,write 1 to set, for pulse_dmpac_out_1_en_dof_read_error
  [1] status_pulse_dmpac_out_1_dof_frame_done — Status ,write 1 to set, for pulse_dmpac_out_1_en_dof_frame_done
  [0] status_pulse_dmpac_out_1_dof_row_done — Status ,write 1 to set, for pulse_dmpac_out_1_en_dof_row_done
0x558 status_reg_pulse_dmpac_out_1_1 access per field — Status Register 22
  [27] status_pulse_dmpac_out_1_tdone_8 rw — Status ,write 1 to set, for pulse_dmpac_out_1_en_tdone_8
  [26] status_pulse_dmpac_out_1_tdone_7 rw — Status ,write 1 to set, for pulse_dmpac_out_1_en_tdone_7
  [25] status_pulse_dmpac_out_1_tdone_1 rw — Status ,write 1 to set, for pulse_dmpac_out_1_en_tdone_1
  [24] status_pulse_dmpac_out_1_tdone_0 rw — Status ,write 1 to set, for pulse_dmpac_out_1_en_tdone_0
  [19] status_pulse_dmpac_out_1_spare_pend_1_l ro — Status for pulse_dmpac_out_1_en_spare_pend_1_l
  [18] status_pulse_dmpac_out_1_spare_pend_1_p ro — Status for pulse_dmpac_out_1_en_spare_pend_1_p
  [17] status_pulse_dmpac_out_1_spare_pend_0_l ro — Status for pulse_dmpac_out_1_en_spare_pend_0_l
  [16] status_pulse_dmpac_out_1_spare_pend_0_p ro — Status for pulse_dmpac_out_1_en_spare_pend_0_p
  [9] status_pulse_dmpac_out_1_spare_dec_1 rw — Status ,write 1 to set, for pulse_dmpac_out_1_en_spare_dec_1
  [8] status_pulse_dmpac_out_1_spare_dec_0 rw — Status ,write 1 to set, for pulse_dmpac_out_1_en_spare_dec_0
  [n] status_pulse_dmpac_out_1_pipe_done_{n} rw (n=0..3) — Status ,write 1 to set, for pulse_dmpac_out_1_en_pipe_done_{n}
0x558 HWA7_scheduler_control access per field — Scheduler Control Register
  [12] debug_rdy rw — '0' -> HWA7 Scheduler resources must not be read during halted state. '1'-> HWA7 Scheduler resources are readable during halted state
  [10:7] state ro — Current state of HWA7 Scheduler
  [6] pause rw — '1' -> pause/suspend scheduler , '0' -> resume scheduler
  [5] strm_en rw — '1' -> Streaming input enable, '0' No streaming input
  [3:1] pipeline_num rw — Pipeline Number of HWA7 Scheduler
  [0] sch_en rw — scheduler enable; write '1' to enable scheduler
0x55C status_reg_pulse_dmpac_out_1_2 — Status Register 23
  [3] status_pulse_dmpac_out_1_watchdogtimer_err_8 — Status ,write 1 to set, for pulse_dmpac_out_1_en_watchdogtimer_err_8
  [2] status_pulse_dmpac_out_1_watchdogtimer_err_7 — Status ,write 1 to set, for pulse_dmpac_out_1_en_watchdogtimer_err_7
  [1] status_pulse_dmpac_out_1_watchdogtimer_err_1 — Status ,write 1 to set, for pulse_dmpac_out_1_en_watchdogtimer_err_1
  [0] status_pulse_dmpac_out_1_watchdogtimer_err_0 — Status ,write 1 to set, for pulse_dmpac_out_1_en_watchdogtimer_err_0
0x55C HWA7_HOP — Scheduler HOP Control Register. Help in detecting eop within scheduler. Once configured, it counts task/channel starts and stops issuing further start. Specifically useful for Head of pipe dma scheduler .
  fields as HWA5_HOP
0x560 status_reg_pulse_dmpac_out_1_3 — Status Register 24
  [n] status_pulse_dmpac_out_1_dru_error_{n} (n=0..31) — Status ,write 1 to set, for pulse_dmpac_out_1_en_dru_error_{n}
0x560 HWA7_WDTimer access per field — Watchdog timer control register
  [24:8] wdtimer_count ro — Current value of HWA7 Scheduler watchdog timer count
  [2] wdtimer_mode rw — Watchdog timeout count '1' -> 128K , '0' -> 64K
  [1] wdtimer_status ro — HWA7 Scheduler watchdog timer status '1' -> Timer Active '0' -> Timer Inactive (count is stable)
  [0] wdtimer_en rw — '1' -> activate watchdog timer for 64K VPAC/DMPAC cycles between task start and task done '0' -> Disable watchdog timer
0x564 status_reg_pulse_dmpac_out_1_4 — Status Register 25
  [n] status_pulse_dmpac_out_1_dru_complete_{n} (n=0..31) — Status ,write 1 to set, for pulse_dmpac_out_1_en_dru_complete_{n}
0x564 HWA7_BW_limiter — Scheduler BW Control Register. Processing unit level BW control. Use DMA to eliminate peak system BW within processing units line/Block
  [22:8] BW_cycle_count — Average Cycle count between successive Task Start
  [4:1] BW_token_count — Max Token count to create average BW
  [0] BW_limiter_en — '1' -> Enable BW limiter function for HWA7 sch, '0' --> Disable
0x568 status_reg_pulse_dmpac_out_1_5 — Status Register 26
  [n] status_pulse_dmpac_out_1_dru_local_out_event_{n} (n=0..31) — Status ,write 1 to set, for pulse_dmpac_out_1_en_dru_local_out_event_{n}
{0x568+4i} HWA7_cons{i}_control (i=0..4) — Controlling consumer socket {i} for HWA7
  [9:1] prod_select — producer select for HWA7 cons socket {i}
  [0] cons_en — '1' -> Consumer socket {i} enable , '0' Disable
